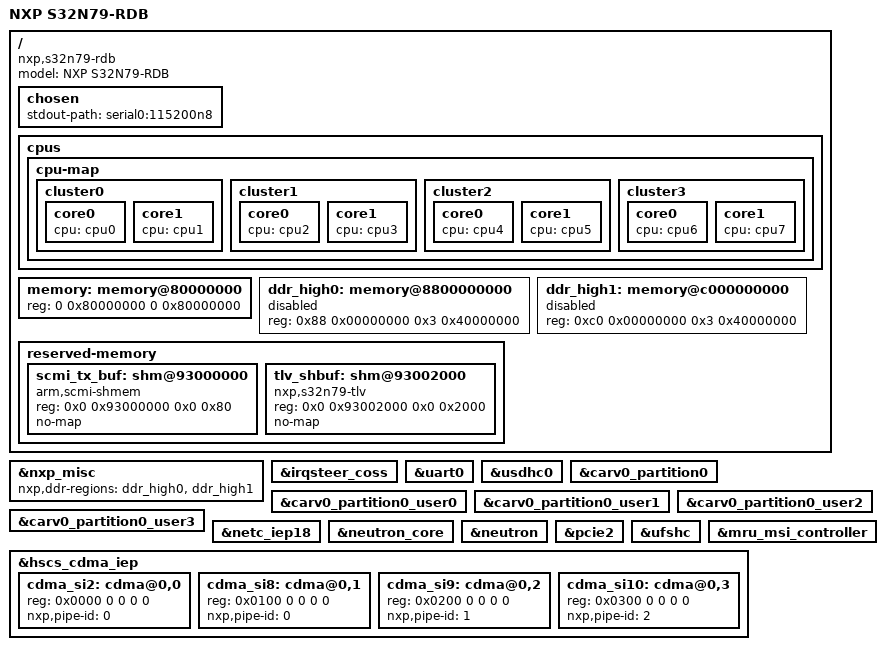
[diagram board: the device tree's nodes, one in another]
// SPDX-License-Identifier: (GPL-2.0+ OR BSD-3-Clause)
/*
 * Copyright 2025-2026 NXP
 */

/dts-v1/;
#include "s32n79-rdb.dtsi"
#include "dt-bindings/memory/s32n7-carv.h"

/ {
	model = "NXP S32N79-RDB";
	compatible = "nxp,s32n79-rdb", "nxp,s32n79";

	chosen {
		stdout-path = "serial0:115200n8";
	};

	cpus {
		cpu-map {
			cluster0 {
				core0 {
					cpu = <&cpu0>;
				};

				core1 {
					cpu = <&cpu1>;
				};
			};

			cluster1 {
				core0 {
					cpu = <&cpu2>;
				};

				core1 {
					cpu = <&cpu3>;
				};
			};

			cluster2 {
				core0 {
					cpu = <&cpu4>;
				};

				core1 {
					cpu = <&cpu5>;
				};
			};

			cluster3 {
				core0 {
					cpu = <&cpu6>;
				};

				core1 {
					cpu = <&cpu7>;
				};
			};
		};
	};

	memory: memory@80000000 {
		device_type = "memory";
		reg = <0 0x80000000 0 0x80000000>;
	};

	ddr_high0: memory@8800000000 {
		device_type = "memory";
		reg = <0x88 0x00000000 0x3 0x40000000>; /* 13GB */
		status = "disabled";
	};

	ddr_high1: memory@c000000000 {
		device_type = "memory";
		reg = <0xc0 0x00000000 0x3 0x40000000>; /* 13GB */
		status = "disabled";
	};

	reserved-memory {
		#address-cells = <2>;
		#size-cells = <2>;
		ranges;

		scmi_tx_buf: shm@93000000 {
			compatible = "arm,scmi-shmem";
			reg = <0x0 0x93000000 0x0 0x80>;
			no-map;
		};

		tlv_shbuf: shm@93002000 {
			compatible = "nxp,s32n79-tlv";
			reg = <0x0 0x93002000 0x0 0x2000>;
			no-map;
		};
	};
};

&nxp_misc {
	nxp,ddr-regions = <&ddr_high0>, <&ddr_high1>;
};

&irqsteer_coss {
	status = "okay";
};

&uart0 {
	status = "okay";
};

&usdhc0 {
	status = "okay";
};

&carv0_partition0 {
	status = "okay";
};

&carv0_partition0_user0 {
	status = "okay";
};

&carv0_partition0_user1 {
	status = "okay";
};

&carv0_partition0_user2 {
	status = "okay";
};

&carv0_partition0_user3 {
	status = "okay";
};

&netc_iep18 {
	status = "okay";
};

&neutron_core {
	status = "okay";
};

&neutron {
	status = "okay";
};

&pcie2 {
	status = "okay";
};

&ufshc {
	status = "okay";
};

&mru_msi_controller {
	status = "okay";
};

&hscs_cdma_iep {
	status = "okay";

	/*
	 * Per-SI cross-SI pipe configuration.
	 *
	 * Each child node binds to one PCI function of the HSCS CDMA RCiEP
	 * (i.e. one Station Interface). 'reg' encodes the BDF using the
	 * standard OpenFirmware PCI binding: phys.hi = (dev<<11) | (fn<<8).
	 *
	 * IERB on this board (PBUS=2 = Linux 0) exposes four SIs:
	 *
	 *   IERB slot   PBUS  RID   PCI BDF             Authorized pipes (PIDaAUR)
	 *   ---------   ----  ----  -----------------   --------------------------
	 *   SI 2          2     0   0001:00:00.0        0 (<->SI8), 1 (<->SI9), 2 (<->SI10)
	 *   SI 8          2     1   0001:00:00.1        0 (<->SI2)
	 *   SI 9          2     2   0001:00:00.2        1 (<->SI2)
	 *   SI 10         2     3   0001:00:00.3        2 (<->SI2)
	 *
	 * The current driver uses a single 'nxp,pipe-id' per cdev (one TX
	 * ring + one RX ring per SI), so SI 2 can only be on one of pipes
	 * 0/1/2 at a time. Default is pipe 0 (SI 2 <-> SI 8). To exercise
	 * pipe 1 or pipe 2, change SI 2's nxp,pipe-id to <1> or <2>; the
	 * peer SI (SI 9 / SI 10) already has the matching value.
	 *
	 * SIs whose pipe peer isn't co-configured (e.g. SI 9 while SI 2 is
	 * on pipe 0) will time out on any pipe submit. If you don't want
	 * that, drop nxp,pipe-id on those nodes - the driver falls back to
	 * single-SI memcpy mode for them.
	 */
	cdma_si2: cdma@0,0 {
		reg = <0x0000 0 0 0 0>;
		nxp,pipe-id = <0>;
	};

	cdma_si8: cdma@0,1 {
		reg = <0x0100 0 0 0 0>;
		nxp,pipe-id = <0>;
	};

	cdma_si9: cdma@0,2 {
		reg = <0x0200 0 0 0 0>;
		nxp,pipe-id = <1>;
	};

	cdma_si10: cdma@0,3 {
		reg = <0x0300 0 0 0 0>;
		nxp,pipe-id = <2>;
	};
};
